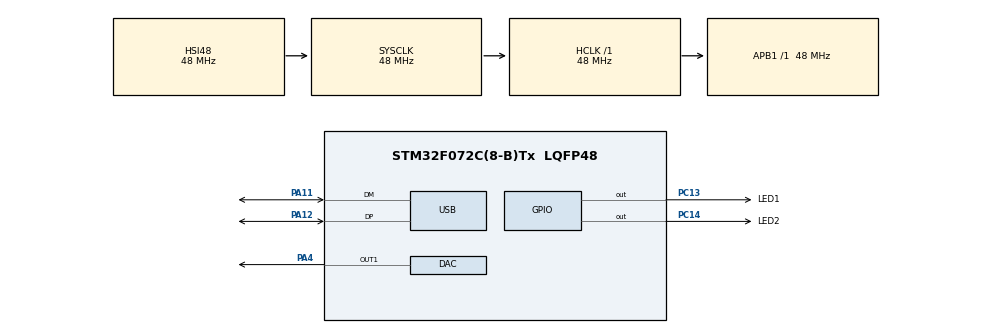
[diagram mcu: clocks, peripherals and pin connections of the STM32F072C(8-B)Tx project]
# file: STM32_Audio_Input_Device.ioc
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DAC.DAC_Trigger=DAC_TRIGGER_T2_TRGO
Dma.DAC_CH1.0.Direction=DMA_MEMORY_TO_PERIPH
Dma.DAC_CH1.0.Instance=DMA1_Channel3
Dma.DAC_CH1.0.MemDataAlignment=DMA_MDATAALIGN_HALFWORD
Dma.DAC_CH1.0.MemInc=DMA_MINC_ENABLE
Dma.DAC_CH1.0.Mode=DMA_NORMAL
Dma.DAC_CH1.0.PeriphDataAlignment=DMA_PDATAALIGN_HALFWORD
Dma.DAC_CH1.0.PeriphInc=DMA_PINC_DISABLE
Dma.DAC_CH1.0.Priority=DMA_PRIORITY_LOW
Dma.Request0=DAC_CH1
Mcu.Family=STM32F0
Mcu.Name=STM32F072C(8-B)Tx
Mcu.Package=LQFP48
NVIC.DMA1_Channel2_3_IRQn=true\:0\:0\:false\:false\:true\:true\:true
NVIC.USB_IRQn=true\:0\:0\:false\:false\:true\:false\:true
PA11.Mode=Device
PA11.Signal=USB_DM
PA12.Mode=Device
PA12.Signal=USB_DP
PA13.Mode=Serial_Wire
PA13.Signal=SYS_SWDIO
PA14.Mode=Serial_Wire
PA14.Signal=SYS_SWCLK
PA4.Signal=COMP_DAC1_group
PC13.GPIO_Label=LED1
PC13.Signal=GPIO_Output
PC14-OSC32_IN.GPIO_Label=LED2
PC14-OSC32_IN.Signal=GPIO_Output
ProjectManager.HeapSize=0x200
ProjectManager.StackSize=0x400
ProjectManager.TargetToolchain=STM32CubeIDE
RCC.AHBFreq_Value=48000000
RCC.APB1Freq_Value=48000000
RCC.APB1TimFreq_Value=48000000
RCC.HCLKFreq_Value=48000000
RCC.SYSCLKFreq_VALUE=48000000
RCC.SYSCLKSource=RCC_SYSCLKSOURCE_HSI48
SH.COMP_DAC1_group.0=DAC_OUT1,DAC_OUT1
TIM2.Channel-Output\ Compare1\ No\ Output=TIM_CHANNEL_1
TIM2.Period=2172
TIM2.TIM_MasterOutputTrigger=TIM_TRGO_OC1
USB_DEVICE.CLASS_NAME_FS=AUDIO
USB_DEVICE.VirtualMode=Audio
USB_DEVICE.VirtualModeFS=Audio_FS
VP_TIM2_VS_ClockSourceINT.Mode=Internal
VP_TIM2_VS_no_output1.Mode=Output Compare1 No Output
VP_USB_DEVICE_VS_USB_DEVICE_AUDIO_FS.Mode=AUDIO_FS
board=custom

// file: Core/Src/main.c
/* USER CODE BEGIN Header */
/**
  ******************************************************************************
  * @file           : main.c
  * @brief          : Main program body
  ******************************************************************************
  * @attention
  *
  * <h2><center>&copy; Copyright (c) 2020 STMicroelectronics.
  * All rights reserved.</center></h2>
  *
  * This software component is licensed by ST under BSD 3-Clause license,
  * the "License"; You may not use this file except in compliance with the
  * License. You may obtain a copy of the License at:
  *                        opensource.org/licenses/BSD-3-Clause
  *
  ******************************************************************************
  */
/* USER CODE END Header */

#include "main.h"
#include "usb_device.h"

/* USER CODE BEGIN Includes */
#include "usbd_audio_if.h"
/* USER CODE END Includes */

/* USER CODE BEGIN PTD */
uint16_t a[100];
/* USER CODE END PTD */

DAC_HandleTypeDef hdac;
DMA_HandleTypeDef hdma_dac_ch1;

TIM_HandleTypeDef htim2;

void SystemClock_Config(void);
static void MX_GPIO_Init(void);
static void MX_DMA_Init(void);
static void MX_DAC_Init(void);
static void MX_TIM2_Init(void);

int main(void)
{

  /* MCU Configuration--------------------------------------------------------*/

  /* Reset of all peripherals, Initializes the Flash interface and the Systick. */
  HAL_Init();

  /* Configure the system clock */
  SystemClock_Config();

  /* USER CODE BEGIN SysInit */

  for(int i = 0; i < 100; i++)
  {
	  a[i] = i*30;
  }

  /* USER CODE END SysInit */

  /* Initialize all configured peripherals */
  MX_GPIO_Init();
  MX_DMA_Init();
  MX_USB_DEVICE_Init();
  MX_DAC_Init();
  MX_TIM2_Init();
  /* USER CODE BEGIN 2 */
//  HAL_DAC_Start_DMA(&hdac, DAC_CHANNEL_1, (uint32_t *) a, 100, DAC_ALIGN_12B_R);
//  HAL_TIM_OC_Start_IT(&htim2,TIM_CHANNEL_1);

  /* USER CODE END 2 */

  /* Infinite loop */
  while (1)
  {

    /* USER CODE BEGIN 3 */
	  // Toggle the LEDs for fun
//	  HAL_GPIO_TogglePin(LED1_GPIO_Port, LED1_Pin);
//	  HAL_GPIO_TogglePin(LED2_GPIO_Port, LED2_Pin);
	  HAL_GPIO_WritePin(LED1_GPIO_Port, LED1_Pin, GPIO_PIN_RESET);
	  HAL_Delay(1);
  }
  /* USER CODE END 3 */
}

void SystemClock_Config(void)
{
  RCC_OscInitTypeDef RCC_OscInitStruct = {0};
  RCC_ClkInitTypeDef RCC_ClkInitStruct = {0};
  RCC_PeriphCLKInitTypeDef PeriphClkInit = {0};

  /** Initializes the CPU, AHB and APB busses clocks
  */
  RCC_OscInitStruct.OscillatorType = RCC_OSCILLATORTYPE_HSI48;
  RCC_OscInitStruct.HSI48State = RCC_HSI48_ON;
  RCC_OscInitStruct.PLL.PLLState = RCC_PLL_NONE;
  if (HAL_RCC_OscConfig(&RCC_OscInitStruct) != HAL_OK)
  {
    Error_Handler();
  }
  /** Initializes the CPU, AHB and APB busses clocks
  */
  RCC_ClkInitStruct.ClockType = RCC_CLOCKTYPE_HCLK|RCC_CLOCKTYPE_SYSCLK
                              |RCC_CLOCKTYPE_PCLK1;
  RCC_ClkInitStruct.SYSCLKSource = RCC_SYSCLKSOURCE_HSI48;
  RCC_ClkInitStruct.AHBCLKDivider = RCC_SYSCLK_DIV1;
  RCC_ClkInitStruct.APB1CLKDivider = RCC_HCLK_DIV1;

  if (HAL_RCC_ClockConfig(&RCC_ClkInitStruct, FLASH_LATENCY_1) != HAL_OK)
  {
    Error_Handler();
  }
  PeriphClkInit.PeriphClockSelection = RCC_PERIPHCLK_USB;
  PeriphClkInit.UsbClockSelection = RCC_USBCLKSOURCE_HSI48;

  if (HAL_RCCEx_PeriphCLKConfig(&PeriphClkInit) != HAL_OK)
  {
    Error_Handler();
  }
}

static void MX_DAC_Init(void)
{

  DAC_ChannelConfTypeDef sConfig = {0};

  /** DAC Initialization
  */
  hdac.Instance = DAC;
  if (HAL_DAC_Init(&hdac) != HAL_OK)
  {
    Error_Handler();
  }
  /** DAC channel OUT1 config
  */
  sConfig.DAC_Trigger = DAC_TRIGGER_T2_TRGO;
  sConfig.DAC_OutputBuffer = DAC_OUTPUTBUFFER_ENABLE;
  if (HAL_DAC_ConfigChannel(&hdac, &sConfig, DAC_CHANNEL_1) != HAL_OK)
  {
    Error_Handler();
  }

}

static void MX_TIM2_Init(void)
{

  TIM_ClockConfigTypeDef sClockSourceConfig = {0};
  TIM_MasterConfigTypeDef sMasterConfig = {0};
  TIM_OC_InitTypeDef sConfigOC = {0};

  htim2.Instance = TIM2;
  htim2.Init.Prescaler = 0;
  htim2.Init.CounterMode = TIM_COUNTERMODE_UP;
  htim2.Init.Period = 2172;
  htim2.Init.ClockDivision = TIM_CLOCKDIVISION_DIV1;
  htim2.Init.AutoReloadPreload = TIM_AUTORELOAD_PRELOAD_DISABLE;
  if (HAL_TIM_Base_Init(&htim2) != HAL_OK)
  {
    Error_Handler();
  }
  sClockSourceConfig.ClockSource = TIM_CLOCKSOURCE_INTERNAL;
  if (HAL_TIM_ConfigClockSource(&htim2, &sClockSourceConfig) != HAL_OK)
  {
    Error_Handler();
  }
  if (HAL_TIM_OC_Init(&htim2) != HAL_OK)
  {
    Error_Handler();
  }
  sMasterConfig.MasterOutputTrigger = TIM_TRGO_OC1;
  sMasterConfig.MasterSlaveMode = TIM_MASTERSLAVEMODE_DISABLE;
  if (HAL_TIMEx_MasterConfigSynchronization(&htim2, &sMasterConfig) != HAL_OK)
  {
    Error_Handler();
  }
  sConfigOC.OCMode = TIM_OCMODE_TIMING;
  sConfigOC.Pulse = 0;
  sConfigOC.OCPolarity = TIM_OCPOLARITY_HIGH;
  sConfigOC.OCFastMode = TIM_OCFAST_DISABLE;
  if (HAL_TIM_OC_ConfigChannel(&htim2, &sConfigOC, TIM_CHANNEL_1) != HAL_OK)
  {
    Error_Handler();
  }

}

static void MX_DMA_Init(void)
{

  /* DMA controller clock enable */
  __HAL_RCC_DMA1_CLK_ENABLE();

  /* DMA interrupt init */
  /* DMA1_Channel2_3_IRQn interrupt configuration */
  HAL_NVIC_SetPriority(DMA1_Channel2_3_IRQn, 0, 0);
  HAL_NVIC_EnableIRQ(DMA1_Channel2_3_IRQn);

}

static void MX_GPIO_Init(void)
{
  GPIO_InitTypeDef GPIO_InitStruct = {0};

  /* GPIO Ports Clock Enable */
  __HAL_RCC_GPIOC_CLK_ENABLE();
  __HAL_RCC_GPIOA_CLK_ENABLE();

  /*Configure GPIO pin Output Level */
  HAL_GPIO_WritePin(GPIOC, LED1_Pin|LED2_Pin, GPIO_PIN_RESET);

  /*Configure GPIO pins : LED1_Pin LED2_Pin */
  GPIO_InitStruct.Pin = LED1_Pin|LED2_Pin;
  GPIO_InitStruct.Mode = GPIO_MODE_OUTPUT_PP;
  GPIO_InitStruct.Pull = GPIO_NOPULL;
  GPIO_InitStruct.Speed = GPIO_SPEED_FREQ_LOW;
  HAL_GPIO_Init(GPIOC, &GPIO_InitStruct);

}

/* USER CODE BEGIN 4 */

void HAL_DAC_ConvCpltCallbackCh1(DAC_HandleTypeDef* hdac)
{
  /* Prevent unused argument(s) compilation warning */
  TransferComplete_CallBack_FS();
//	HAL_DAC_Start_DMA(hdac, DAC_CHANNEL_1, (uint32_t *) a, 100, DAC_ALIGN_12B_R);
  /* NOTE : This function should not be modified, when the callback is needed,
            the HAL_DAC_ConvCpltCallbackCh1 could be implemented in the user file
   */
}

void HAL_DAC_ConvHalfCpltCallbackCh1(DAC_HandleTypeDef* hdac)
{
  /* Prevent unused argument(s) compilation warning */
  HalfTransfer_CallBack_FS();
  /* NOTE : This function should not be modified, when the callback is needed,
            the HAL_DAC_ConvCpltCallbackCh1 could be implemented in the user file
   */
}

/* USER CODE END 4 */

void Error_Handler(void)
{
}

/************************ (C) COPYRIGHT STMicroelectronics *****END OF FILE****/
